# ATtiny43U device description
Architecture: AVR8; Family: tinyAVR
Registers are 8-bit, access not given, no defined reset value unless marked. A register's access mark holds for its fields unless they carry their own. Offsets are from the block's base; [hi:lo] are bit positions; {n}, {i} and the like mark numbered series.

## TC0 (TC8 module) — Timer/Counter, 8-bit
Instances: TC0 0x00
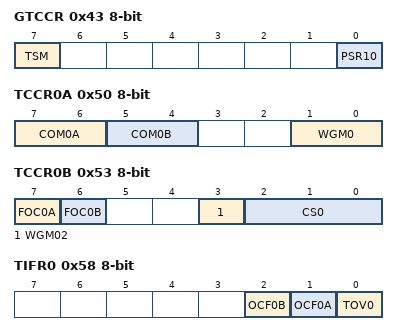
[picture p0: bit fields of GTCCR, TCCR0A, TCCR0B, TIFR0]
0x43 GTCCR — General Timer/Counter Control Register
  [7] TSM — Timer/Counter Synchronization Mode
  [0] PSR10 — Prescaler Reset Timer/CounterN
0x50 TCCR0A — Timer/Counter Control Register A
  [7:6] COM0A — Compare Match Output A Mode bits
  [5:4] COM0B — Compare Match Output B Mode bits
  [1:0] WGM0 — Waveform Generation Mode bits
0x52 TCNT0 — Timer/Counter0
0x53 TCCR0B — Timer/Counter Control Register B
  [7] FOC0A — Force Output Compare A
  [6] FOC0B — Force Output Compare B
  [3] WGM02 — Waveform Generation Mode bit 2
  [2:0] CS0 — Clock Select bits
    0=No Clock Source (Stopped); 1=Running, No Prescaling; 2=Running, CLK/8; 3=Running, CLK/64; 4=Running, CLK/256; 5=Running, CLK/1024; 6=Running, ExtClk Tx Falling Edge; 7=Running, ExtClk Tx Rising Edge
0x56 OCR0A — Timer/Counter0 Output Compare Register A
0x58 TIFR0 — Timer/Counter0 Interrupt Flag Register
  [2] OCF0B — Timer/Counter0 Output Compare Flag B
  [1] OCF0A — Timer/Counter0 Output Compare Flag A
  [0] TOV0 — Timer/Counter0 Overflow Flag
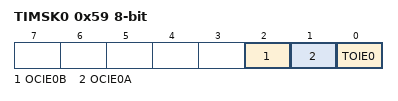
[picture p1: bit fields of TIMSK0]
0x59 TIMSK0 — Timer/Counter Interrupt Mask Register
  [2] OCIE0B — Timer/Counter0 Output Compare Match B Interrupt Enable
  [1] OCIE0A — Timer/Counter0 Output Compare Match A Interrupt Enable
  [0] TOIE0 — Timer/Counter0 Overflow Interrupt Enable
0x5C OCR0B — Timer/Counter0 Output Compare Register B

## TC1 (TC8 module) — Timer/Counter, 8-bit
Instances: TC1 0x00
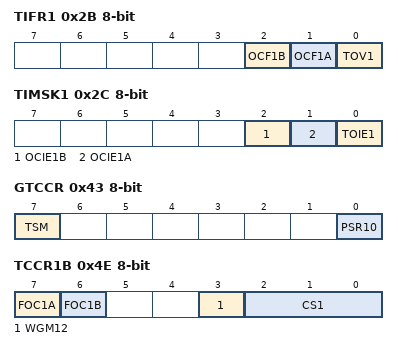
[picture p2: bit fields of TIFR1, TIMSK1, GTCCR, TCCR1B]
0x2B TIFR1 — Timer/Counter1 Interrupt Flag Register
  [2] OCF1B — Timer/Counter1 Output Compare Flag B
  [1] OCF1A — Timer/Counter1 Output Compare Flag A
  [0] TOV1 — Timer/Counter1 Overflow Flag
0x2C TIMSK1 — Timer/Counter Interrupt Mask Register
  [2] OCIE1B — Timer/Counter1 Output Compare Match B Interrupt Enable
  [1] OCIE1A — Timer/Counter1 Output Compare Match A Interrupt Enable
  [0] TOIE1 — Timer/Counter1 Overflow Interrupt Enable
0x43 GTCCR — General Timer/Counter Control Register
  [7] TSM — Timer/Counter Synchronization Mode
  [0] PSR10 — Prescaler Reset Timer/CounterN
0x4B OCR1B — Timer/Counter1 Output Compare Register B
0x4C OCR1A — Timer/Counter1 Output Compare Register A
0x4D TCNT1 — Timer/Counter1
0x4E TCCR1B — Timer/Counter Control Register B
  [7] FOC1A — Force Output Compare A
  [6] FOC1B — Force Output Compare B
  [3] WGM12 — Waveform Generation Mode bit 2
  [2:0] CS1 — Clock Select bits
    0=No Clock Source (Stopped); 1=Running, No Prescaling; 2=Running, CLK/8; 3=Running, CLK/64; 4=Running, CLK/256; 5=Running, CLK/1024; 6=Running, ExtClk Tx Falling Edge; 7=Running, ExtClk Tx Rising Edge
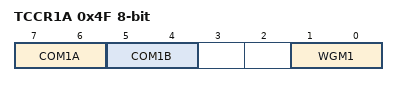
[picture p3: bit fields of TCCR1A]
0x4F TCCR1A — Timer/Counter1 Control Register A
  [7:6] COM1A — Compare Match Output A Mode bits
  [5:4] COM1B — Compare Match Output B Mode bits
  [1:0] WGM1 — Waveform Generation Mode bits

## BOOT_LOAD — Bootloader
Instances: BOOT_LOAD 0x00
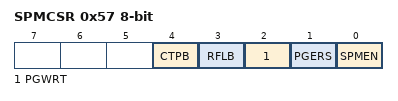
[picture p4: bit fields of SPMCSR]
0x57 SPMCSR — Store Program Memory Control Register
  [4] CTPB — Clear temporary page buffer
  [3] RFLB — Read fuse and lock bits
  [2] PGWRT — Page Write
  [1] PGERS — Page Erase
  [0] SPMEN — Store Program Memory Enable

## CPU — CPU Registers
Instances: CPU 0x00
Parameters: CORE_VERSION=V2, NEW_INSTRUCTIONS=lpm rd,z+
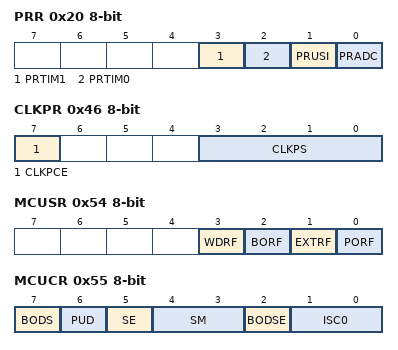
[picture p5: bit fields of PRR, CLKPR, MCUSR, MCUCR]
0x20 PRR — Power Reduction Register
  [3] PRTIM1 — Power Reduction Timer/Counter1
  [2] PRTIM0 — Power Reduction Timer/Counter0
  [1] PRUSI — Power Reduction USI
  [0] PRADC — Power Reduction ADC
{0x33+i} GPIOR{i} (i=0..2) — General Purpose I/O Register {i}
0x46 CLKPR — Clock Prescale Register
  [7] CLKPCE — Clock Prescaler Change Enable
  [3:0] CLKPS — Clock Prescaler Select Bits
    0=1; 1=2; 2=4; 3=8; 4=16; 5=32; 6=64; 7=128; 8=256
0x51 OSCCAL — Oscillator Calibration Value
  [7:0] OSCCAL — Oscillator Calibration
0x54 MCUSR — MCU Status Register
  [3] WDRF — Watchdog Reset Flag
  [2] BORF — Brown-out Reset Flag
  [1] EXTRF — External Reset Flag
  [0] PORF — Power-on reset flag
0x55 MCUCR — MCU Control Register
  [7] BODS — BOD Sleep
  [6] PUD — Pull-Up Disable
  [5] SE — Sleep Enable
  [4:3] SM — Sleep Mode Select Bits
    0=IDLE; 1=ADC (ADC Noise Reduction (If Available)); 2=PDOWN (Power Down); 3=STDBY (Standby)
  [2] BODSE — BOD Sleep Enable
  [1:0] ISC0 — Interrupt Sense Control 0 Bits
    0=Low Level of INTX; 1=Any Logical Change in INTX; 2=Falling Edge of INTX; 3=Rising Edge of INTX
0x5D SP 16-bit bits used 8:0 — Stack Pointer
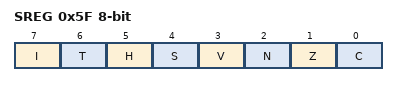
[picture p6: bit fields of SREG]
0x5F SREG — Status Register
  [7] I — Global Interrupt Enable
  [6] T — Bit Copy Storage
  [5] H — Half Carry Flag
  [4] S — Sign Bit
  [3] V — Two's Complement Overflow Flag
  [2] N — Negative Flag
  [1] Z — Zero Flag
  [0] C — Carry Flag
Value list OSCCAL_VALUE_ADDRESSES: 0=8_0_MHz

## EXINT — External Interrupts
Instances: EXINT 0x00
0x32 PCMSK0 — Pin Change Enable Mask Byte 0
0x40 PCMSK1 — Pin Change Enable Mask Byte 1
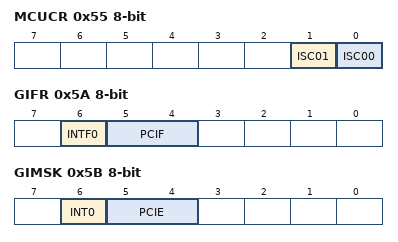
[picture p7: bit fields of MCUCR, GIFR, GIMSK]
0x55 MCUCR — MCU Control Register
  [1] ISC01 — Interrupt Sense Control 0 Bit 1
  [0] ISC00 — Interrupt Sense Control 0 Bit 0
    0=Low Level of INTX; 1=Any Logical Change of INTX; 2=Falling Edge of INTX; 3=Rising Edge of INTX
0x5A GIFR — General Interrupt Flag register
  [6] INTF0 — External Interrupt Flag 0
  [5:4] PCIF — Pin Change Interrupt Flags
0x5B GIMSK — General Interrupt Mask Register
  [6] INT0 — External Interrupt Request 0 Enable
  [5:4] PCIE — Pin Change Interrupt Enables

## AC — Analog Comparator
Instances: AC 0x00
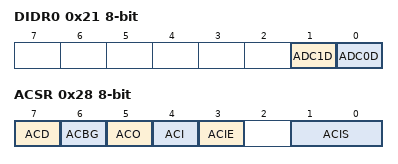
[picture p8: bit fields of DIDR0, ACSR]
0x21 DIDR0
  [1] ADC1D — ADC 1 Digital input buffer disable
  [0] ADC0D — ADC 0 Digital input buffer disable
0x23 ADCSRB — ADC Control and Status Register B
  [6] ACME — Analog Comparator Multiplexer Enable
0x28 ACSR — Analog Comparator Control And Status Register
  [7] ACD — Analog Comparator Disable
  [6] ACBG — Analog Comparator Bandgap Select
  [5] ACO — Analog Compare Output
  [4] ACI — Analog Comparator Interrupt Flag
  [3] ACIE — Analog Comparator Interrupt Enable
  [1:0] ACIS — Analog Comparator Interrupt Mode Select bits
    0=Interrupt on Toggle; 2=Interrupt on Falling Edge; 3=Interrupt on Rising Edge

## ADC — Analog-to-Digital Converter
Instances: ADC 0x00
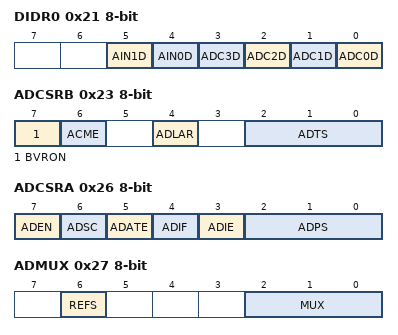
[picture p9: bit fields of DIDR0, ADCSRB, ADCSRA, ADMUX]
0x21 DIDR0 — Digital Input Disable Register 0
  [5] AIN1D — Analog Comparator IO
  [4] AIN0D — Analog Comparator IO
  [n] ADC{n}D (n=0..3) — ADC{n} Digital Input Disable
0x23 ADCSRB — ADC Control and Status Register B
  [7] BVRON — Boost Regulator Status Bit
  [6] ACME — Analog Comparator Multiplexer Enable
  [4] ADLAR — ADC Left Adjust Result
  [2:0] ADTS — ADC Auto Trigger Source bits
    0=Free Running mode; 1=Analog Comparator; 2=External Interrupt Request 0; 3=Timer/Counter0 Compare Match A; 4=Timer/Counter0 Overflow; 5=Timer/Counter1 Compare Match A; 6=Timer/Counter1 Overflow; 7=Timer/Counter1 Capture Match B
0x24 ADC 16-bit — ADC Data Register Bytes
0x26 ADCSRA — ADC Control and Status Register A
  [7] ADEN — ADC Enable
  [6] ADSC — ADC Start Conversion
  [5] ADATE — ADC Auto Trigger Enable
  [4] ADIF — ADC Interrupt Flag
  [3] ADIE — ADC Interrupt Enable
  [2:0] ADPS — ADC Prescaler Select Bits
    0=2; 1=2; 2=4; 3=8; 4=16; 5=32; 6=64; 7=128
0x27 ADMUX — ADC Multiplexer Selection Register
  [6] REFS — Reference Selection Bit
    0=Vcc; 1=Internal 1.1V Voltage Reference
  [2:0] MUX — Analog Channel Selection Bits

## EEPROM
Instances: EEPROM 0x00
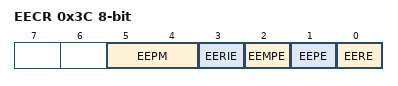
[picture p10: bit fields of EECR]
0x3C EECR — EEPROM Control Register
  [5:4] EEPM — EEPROM Programming Mode Bits
    0=Erase and Write in one operation; 1=Erase Only; 2=Write Only
  [3] EERIE — EEPROM Ready Interrupt Enable
  [2] EEMPE — EEPROM Master Write Enable
  [1] EEPE — EEPROM Write Enable
  [0] EERE — EEPROM Read Enable
0x3D EEDR — EEPROM Data Register
0x3E EEAR bits used 5:0 — EEPROM Address Register
